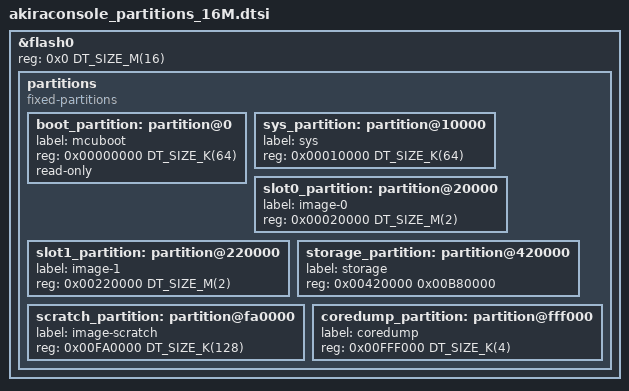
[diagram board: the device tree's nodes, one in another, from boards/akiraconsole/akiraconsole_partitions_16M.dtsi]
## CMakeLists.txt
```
# SPDX-License-Identifier: GPL-3.0-only
cmake_minimum_required(VERSION 3.20.0)

# Suppress Kconfig warnings-as-errors so undefined symbols (during incremental
# migration) do not abort the configuration phase.
set(KCONFIG_WARN_UNDEF OFF CACHE BOOL "" FORCE)
set(KCONFIG_WERROR     OFF CACHE BOOL "" FORCE)

# Board root — this repo contains the `boards/akiraconsole` board definition.
list(APPEND BOARD_ROOT ${CMAKE_CURRENT_LIST_DIR})
list(APPEND DTS_ROOT   ${CMAKE_CURRENT_LIST_DIR})

# AkiraOS is fetched by west into the `akiraos/` sub-directory next to this repo.
find_package(Zephyr REQUIRED HINTS $ENV{ZEPHYR_BASE})
project(akiraconsole_firmware VERSION 1.4.9)

# AkiraOS application sources are provided by the platform repo.
# MUST use add_subdirectory() — not include() — so that CMake sets
# CMAKE_CURRENT_SOURCE_DIR to the akiraos dir when processing its
# CMakeLists.txt.  target_sources() resolves relative paths from the
# internal CMAKE_CURRENT_SOURCE_DIR; include() does NOT update it.
if(EXISTS "${CMAKE_CURRENT_LIST_DIR}/../akiraos/CMakeLists.txt")
  add_subdirectory("${CMAKE_CURRENT_LIST_DIR}/../akiraos"
                   "${CMAKE_CURRENT_BINARY_DIR}/akiraos")
endif()

# ── WAMR include-path fix ───────────────────────────────────────────────────
# WAMR's runtime_lib.cmake registers its headers via directory-scoped
# include_directories().  When AkiraOS is pulled in via add_subdirectory()
# those directory-scoped includes are confined to the akiraos/ CMake scope
# and do NOT propagate to the parent (firmware) scope where 'app' target
# sources are actually compiled.  The result is fatal missing-header errors
# for platform_api_vmcore.h, bh_platform.h, and friends.
# Fix: explicitly add every WAMR include dir that runtime_lib.cmake would
# have registered globally in a standalone AkiraOS build.
if(CONFIG_AKIRA_WASM_RUNTIME)
  set(_wamr "${CMAKE_CURRENT_LIST_DIR}/../akiraos/modules/wasm-micro-runtime")
  target_include_directories(app PRIVATE
    ${_wamr}/core/shared/platform/include   # platform_api_vmcore.h, platform_common.h
    ${_wamr}/core/shared/platform/zephyr    # platform_internal.h (included by platform_common.h)
    ${_wamr}/core/shared/mem-alloc          # mem_alloc.h
    ${_wamr}/core/shared/utils              # bh_common.h, bh_log.h
    ${_wamr}/core/shared/utils/uncommon     # bh_assert.h variants
  )
  # platform_internal.h defines zephyr_fs_desc using struct fs_file_t / fs_dir_t
  # (Zephyr FS types from <zephyr/fs/fs_interface.h>).  When WAMR_BUILD_LIBC_WASI=0
  # zephyr_file.c — the only file that would pull in fs_interface.h — is excluded
  # from the build, leaving those types incomplete for every other translation unit.
  # Force-include the header so all app TUs see the complete struct definitions.
  target_compile_options(app PRIVATE
    "-include" "zephyr/fs/fs_interface.h"
  )
endif()

# ── AkiraConsole product-specific sources ──────────────────────────────────
# These files live in this repo and can be freely modified without touching
# AkiraOS.  Add new console-specific features here.
target_sources(app PRIVATE
  src/console_board.c
)

target_include_directories(app PRIVATE
  ${CMAKE_CURRENT_LIST_DIR}/src
)
```

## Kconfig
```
# SPDX-License-Identifier: Apache-2.0
#
# AkiraConsole Firmware — root Kconfig
#
# 1. Sources AkiraOS Kconfig tree (which itself sources Kconfig.zephyr),
#    making all AKIRA_* symbols available to the firmware config files.
# 2. Sources the product-level Kconfig so console-specific symbols
#    (AKIRA_CONSOLE_*) are visible in menuconfig and .conf files.
rsource "../akiraos/Kconfig"
rsource "src/Kconfig"
```

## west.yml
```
manifest:
  projects:
    # AkiraOS — the embedded platform (OS, drivers, WAMR runtime, native APIs).
    # Track the C0ns0l3-Firmware branch which is the validated working branch
    # for the AkiraConsole hardware.  Swap this for a release tag (e.g.
    # v1.4.10) once that tag is cut and CI is green.
    #
    # import: true  →  west reads AkiraOS/west.yml and pulls in Zephyr v4.3.0
    # plus all its HAL modules transitively.  This is the T2 manifest topology:
    # AkiraConsole-Firmware owns the entry-point; AkiraOS owns the Zephyr pin.
    - name: akiraos
      url: https://github.com/ArturR0k3r/AkiraOS
      revision: C0ns0l3-Firmware
      path: akiraos
      import: true   # brings in Zephyr + HALs from AkiraOS/west.yml

  self:
    path: akiraconsole-firmware
```

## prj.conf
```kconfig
# AkiraConsole product-level Kconfig overlay.
# Board-specific options (ESP32-S3, PSRAM, display, WiFi, BT …) are in
# boards/akiraconsole_esp32s3_procpu.conf and are merged automatically by west.
# Only add overrides here that are specific to the AkiraConsole *product* and
# should not live in the platform (AkiraOS) prj.conf.

# Enable AkiraOS WASM runtime — required gate for all AKIRA_WASM_* symbols.
CONFIG_AKIRA_WASM_RUNTIME=y

# App manager for persistent WASM install/uninstall.
CONFIG_AKIRA_APP_MANAGER=y
```

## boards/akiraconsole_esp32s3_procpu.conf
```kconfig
# BOARD_ZEPHYR: akiraconsole/esp32s3/procpu
# BOARD_CHIP: esp32s3
# BOARD_DESC: Akira Console (ESP32-S3 N16R8)
# BOARD_ALIAS: akiraconsole

# ESP32-S3 Specific Configuration
# ESP32-S3 N16R8 Module: 16MB Flash, 8MB PSRAM (OPI)

###############################################################################
# PSRAM (External SPIRAM) Configuration - 8MB OPI PSRAM
###############################################################################
CONFIG_ESP_SPIRAM=y
CONFIG_ESP_SPIRAM_SIZE=8388608
CONFIG_ESP_SPIRAM_HEAP_SIZE=4194304
CONFIG_SPIRAM_MODE_OCT=y
CONFIG_AKIRA_PSRAM=y
CONFIG_SPIRAM_TYPE_ESPPSRAM64=y
# WASM app thread stacks live in SRAM (not PSRAM) to avoid SPI0 bus conflict.
# On ESP32-S3, PSRAM and internal flash share SPI0; a direct flash read
# (e.g. fs_open via LittleFS) disables SPI0 PSRAM cache, crashing any thread
# whose stack is in PSRAM. 8 KB covers the deepest native call chain in AOT mode
# (WAMR AOT dispatch → native API → Zephyr display/SPI/DMA ≈ 3-4 KB worst case).
# The WAMR instance operand-stack (CONFIG_WAMR_STACK_SIZE=8192) is separate.
# 8 KB halves the SRAM heap requirement vs the old 16 KB, making allocation
# robust against WiFi/BT fragmentation of the 64 KB kernel heap.
CONFIG_AKIRA_WASM_APP_STACK_SIZE=8192
CONFIG_WAMR_AOT_SUPPORT=y
CONFIG_SPIRAM_SPEED_80M=y

# Enable MEMC driver - REQUIRED for PSRAM configuration
# This allows WAMR heap buffer to be placed in PSRAM instead of internal DRAM
CONFIG_MEMC=y

# Optional: Move read-only data to PSRAM to free internal DRAM 
CONFIG_SPIRAM_RODATA=y
CONFIG_SPIRAM_FETCH_INSTRUCTIONS=y



# Skip PSRAM memtest for faster boot (enable for debugging)
CONFIG_ESP_SPIRAM_MEMTEST=n

###############################################################################
# Thread Local Storage - REQUIRED for ESP32-S3 WAMR
###############################################################################
# ESP32-S3 has THREADPTR register (XCHAL_HAVE_THREADPTR=1).
# Without TLS enabled, Zephyr doesn't initialize or manage THREADPTR,
# leaving garbage values that cause crashes when WAMR accesses TLS.
CONFIG_THREAD_LOCAL_STORAGE=y

###############################################################################
# Memory Configuration (with PSRAM)
###############################################################################
# K-heap must exceed ADD_SIZE sum (BT=25600 + WiFi=19456 + POSIX=808 = 45864).
# If HEAP_MEM_POOL_SIZE < 45864, Zephyr uses 45864 as the effective K-heap —
# zero headroom for coex_init (esp_coex_common_malloc_internal_wrapper → k_malloc)
# → coex_env=NULL → ROM emi.c:164 assert.  65536 gives 19672 bytes of headroom.
# Large app allocations use akira_malloc_buffer() → PSRAM via shared_multi_heap.
CONFIG_HEAP_MEM_POOL_SIZE=65536
CONFIG_MAIN_STACK_SIZE=4096
CONFIG_SYSTEM_WORKQUEUE_STACK_SIZE=4096
# Shell backend thread stacks (uart + telnet): 4 K each is sufficient.
CONFIG_SHELL_STACK_SIZE=4096

# Shared Multi-Heap for PSRAM allocation
CONFIG_SHARED_MULTI_HEAP=y


###############################################################################
# Bluetooth
###############################################################################
CONFIG_BT=y
CONFIG_BT_PERIPHERAL=y
CONFIG_BT_DEVICE_NAME="AkiraOS"
CONFIG_BT_DEVICE_NAME_DYNAMIC=y
CONFIG_BT_DEVICE_NAME_MAX=32
CONFIG_BT_MAX_CONN=1
CONFIG_BT_L2CAP_TX_MTU=300
CONFIG_BT_BUF_ACL_RX_SIZE=300
CONFIG_BT_BUF_ACL_TX_SIZE=300


# GATT
CONFIG_BT_GATT_CLIENT=y
CONFIG_BT_ATT_PREPARE_COUNT=1
# Required for dynamic GATT service register/unregister (ble_app_service)
CONFIG_BT_GATT_DYNAMIC_DB=y

# BT Work Queue Stack Sizes
CONFIG_BT_RX_STACK_SIZE=2048
CONFIG_BT_HCI_TX_STACK_SIZE=1024

# Security
CONFIG_BT_SMP=y
CONFIG_BT_SIGNING=y
CONFIG_BT_BONDABLE=y
CONFIG_BT_KEYS_OVERWRITE_OLDEST=y
# Allow both legacy and Secure Connections pairing — older iOS/iPadOS uses legacy
CONFIG_BT_SMP_SC_PAIR_ONLY=n
# Service Changed indication — tells bonded peers (iOS/Android/Windows) to
# re-discover GATT database when firmware updates the attribute table.
# Without this, hosts cache stale handles and disconnect with 0x13.
CONFIG_BT_GATT_SERVICE_CHANGED=y
CONFIG_BT_GATT_CACHING=y

# Bond persistence — saves LTK / IRK to NVS so bonds survive reboot
# Without this the device loses keys on reset → security err 4 on reconnect
CONFIG_SETTINGS=y
CONFIG_SETTINGS_NVS=y
CONFIG_BT_SETTINGS=y

# Device Information Service (optional - disable to save memory)
# CONFIG_BT_DIS=y
# CONFIG_BT_DIS_STR_MAX=21
# Battery Service (optional - disable to save memory)
# Battery Service - mandatory for HOGP (iOS won't complete HID enumeration without it)
CONFIG_BT_BAS=y

###############################################################################
# HID & BT (BT-capable board — moved from prj.conf)
###############################################################################
CONFIG_AKIRA_HID=y
CONFIG_AKIRA_HID_MODE_KB_MOUSE=y
CONFIG_AKIRA_BT_HID=y


###############################################################################
# ESP32-S3 WiFi/BT
###############################################################################
# Base network stack — required for WIFI_ESP32 to satisfy NET_L2_ETHERNET deps
CONFIG_NETWORKING=y
CONFIG_NET_IPV4=y
CONFIG_WIFI=y
CONFIG_WIFI_ESP32=y
CONFIG_ESP_WIFI_HEAP_SPIRAM=y
# NOTE: CONFIG_ESP32_WIFI_NET_ALLOC_SPIRAM must NOT be set on ESP32-S3 when
# Bluetooth is active.  The BT controller ROM blob accesses WiFi coexistence
# state (emi.c) via shared DRAM structs; moving those to SPIRAM makes the ROM
# code fault with "BLE assert emi.c 164".  DRAM budget is met instead by the
# LVGL SPIRAM placement flags (LV_Z_VDB_CUSTOM_SECTION + MEMORY_POOL_CUSTOM)
# and reduced stack/buffer sizes — no WiFi/net noinit relocation needed.
CONFIG_ESP32_WIFI_STA_AUTO_DHCPV4=y
CONFIG_NET_L2_WIFI_MGMT=y
CONFIG_SHELL_BACKEND_TELNET=y
CONFIG_SHELL_TELNET_SUPPORT_COMMAND=y
CONFIG_NET_SOCKETS_OFFLOAD=y

# Bluetooth Controller Configuration
CONFIG_ESP32_BT_CONTROLLER_STACK_SIZE=4096
CONFIG_ESP32_BT_CONTROLLER_TASK_PRIO=2

# SPI for display
CONFIG_SPI=y

# Sensor support
CONFIG_I2C=y
CONFIG_SENSOR=y

# Disable AMPDU if you're still having issues (reduces memory usage)
CONFIG_ESP32_WIFI_AMPDU_TX_ENABLED=n
CONFIG_ESP32_WIFI_AMPDU_RX_ENABLED=n
# AMPDU disabled → 6 static RX buffers is enough; saves ~3.2 KB vs default 10
CONFIG_ESP32_WIFI_STATIC_RX_BUFFER_NUM=6

# Place large static assets into PSRAM where available
CONFIG_AKIRA_FONTS_IN_PSRAM=y
CONFIG_AKIRA_FRAMEBUFFER_IN_PSRAM=y

###############################################################################
# WAMR Memory Configuration - Using PSRAM for large buffers
###############################################################################
# With CONFIG_MEMC=y and ESP32-S3 PSRAM support,
# the WAMR heap buffer is placed in external SPIRAM
# This allows much larger WAMR heap without consuming internal DRAM
# Configure WAMR heap size for PSRAM placement
CONFIG_WAMR_HEAP_SIZE=1048576

# Limit max containers to save memory
CONFIG_MAX_CONTAINERS=2

###############################################################################
# Logging - Use immediate mode for debugging
###############################################################################
CONFIG_LOG_MODE_IMMEDIATE=y

CONFIG_AKIRA_BT_ECHO=n
CONFIG_AKIRA_EMBEDDED_WEB=y

###############################################################################
# Display & Input
###############################################################################
CONFIG_DISPLAY=y
CONFIG_MIPI_DBI=y


###############################################################################
# SD Card Support — SPI-SDHC via GPIO11/12/13/14
# MOSI=GPIO11, SCK=GPIO12, MISO=GPIO13, CS=GPIO14
# DTS node spi_sdhc0 on SPI2 (see akiraconsole_esp32s3_procpu.overlay)
# DISK_DRIVER_SDMMC is auto-selected by DTS (zephyr,sdmmc-disk node enabled)
###############################################################################
CONFIG_AKIRA_SD_CARD=y
CONFIG_SDHC=y
CONFIG_SDMMC_STACK=y
CONFIG_FILE_SYSTEM=y
CONFIG_FAT_FILESYSTEM_ELM=y
CONFIG_FS_FATFS_LFN=y
CONFIG_AKIRA_APP_SOURCE_SD=y


###############################################################################
# USB Stack
# HID only: 8–64 byte interrupt transfers. 2 KB is sufficient for the
# DWC2 IRQ bottom-half and the USBD event dispatcher.
###############################################################################
CONFIG_UDC_DWC2_STACK_SIZE=2048
CONFIG_USBD_THREAD_STACK_SIZE=2048

###############################################################################
# LR1121 LoRa Transceiver Support
###############################################################################
CONFIG_AKIRA_MODULE_RF=n
CONFIG_AKIRA_RF_FRAMEWORK=n
CONFIG_AKIRA_LR1121=n

###############################################################################
# TFT Display Driver — DC=GPIO9, RST=GPIO45, CS=GPIO10 (same for both)
# Default: ST7789V.  To use AkiraOS ILI9341, swap the three lines below:
#   comment ST7789V + MIPI_DBI_SPI, uncomment AKIRA_ILI9341_DRIVER.
###############################################################################
CONFIG_ST7789V=y
CONFIG_MIPI_DBI_SPI=y
#CONFIG_AKIRA_ILI9341_DRIVER=y

# Display and SPI log levels — DBG floods LOG_MODE_IMMEDIATE and stalls SPI
CONFIG_DISPLAY_LOG_LEVEL_WRN=y
CONFIG_MIPI_DBI_LOG_LEVEL_WRN=y
CONFIG_SPI_LOG_LEVEL_WRN=y


###############################################################################
# Flash configuration
###############################################################################
CONFIG_ESPTOOLPY_FLASHSIZE_16MB=y
CONFIG_ESPTOOLPY_FLASHMODE_DIO=y
CONFIG_ESPTOOLPY_FLASHFREQ_40M=y


###############################################################################
# Akira USB
###############################################################################
CONFIG_AKIRA_USB=y
CONFIG_AKIRA_USB_HID=y

CONFIG_USBD_LOG_LEVEL_INF=n
CONFIG_USBD_HID_LOG_LEVEL_INF=n
CONFIG_UDC_DRIVER_LOG_LEVEL_WRN=n
CONFIG_UDC_DRIVER_LOG_LEVEL_INF=n

###############################################################################
# Sensors - LSM6DS3 IMU on I2C0 (SDA=GPIO8, SCL=GPIO18)
# LSM6DS3TR-C shares WHO_AM_I 0x6A with LSM6DSL — no custom driver needed
###############################################################################
CONFIG_AKIRA_LSM6DS3_DRIVER=y
# WASM-level Timer/I2C APIs
CONFIG_AKIRA_WASM_TIMER=y

###############################################################################
# IPC / HID — PSRAM build: AKIRA_BULK_BSS routes arrays to .ext_ram.bss.
# MSG_MAX_SIZE=256 and QUEUE_DEPTH=4 are board overrides above prj.conf defaults.
###############################################################################
CONFIG_AKIRA_HID_MAX_ACTIONS=16
CONFIG_AKIRA_IPC_MSG_MAX_SIZE=256
CONFIG_AKIRA_IPC_QUEUE_DEPTH=4
CONFIG_AKIRA_WASM_I2C=y

###############################################################################
# WASM API Surface — hardware-specific APIs enabled on this board
###############################################################################
CONFIG_AKIRA_WASM_HID=y
CONFIG_AKIRA_WASM_POWER=y

###############################################################################
# Input subsystem — activates gpio-keys DTS driver for AkiraConsole buttons
###############################################################################
CONFIG_INPUT=y
CONFIG_AKIRA_INPUT_API=y
CONFIG_AKIRA_WASM_INPUT=y

###############################################################################
# System API — SD card WASM scanner (requires app.control cap, SD card above)
###############################################################################
CONFIG_AKIRA_SYSTEM_API=y

###############################################################################
# Boot shell — auto-launch akira_shell WASM app after app_manager_init()
# NOTE: With CONFIG_AKIRA_OS_SHELL=y the OS shell starts via SYS_INIT at
# APPLICATION level and does not need BOOT_SHELL.  Keep BOOT_SHELL entries
# only while WASM akira_shell is still installed during the transition.
###############################################################################
CONFIG_AKIRA_BOOT_SHELL=n
# CONFIG_AKIRA_BOOT_SHELL_NAME="akira_shell"
# CONFIG_AKIRA_BOOT_SHELL_RESTART=y

###############################################################################
# Native OS Shell (LVGL-based, C code, runs as a Zephyr thread)
# Replaces the WASM akira_shell app. Depends on DISPLAY && LVGL.
###############################################################################
CONFIG_AKIRA_OS_SHELL=y
CONFIG_AKIRA_HOME_BUTTON_GPIO=17
CONFIG_AKIRA_OS_VERSION="1.4.9-Gl1tch"

###############################################################################
# LVGL — required by the native OS shell
# VDB (virtual draw buffer) and LVGL heap are placed in SPIRAM via the
# .lvgl_buf / .lvgl_heap linker sections (ESP32-S3 GDMA covers PSRAM).
# This frees ~62 KB of internal DRAM for Zephyr thread stacks and BT/USB.
###############################################################################
CONFIG_LVGL=y
CONFIG_LV_COLOR_DEPTH_16=y
CONFIG_LV_Z_VDB_SIZE=10
CONFIG_LV_Z_VDB_CUSTOM_SECTION=y
CONFIG_LV_Z_MEM_POOL_SIZE=32768
CONFIG_LV_Z_MEMORY_POOL_CUSTOM_SECTION=y
CONFIG_LV_FONT_MONTSERRAT_14=y
CONFIG_LV_FONT_MONTSERRAT_20=y
CONFIG_LV_FONT_MONTSERRAT_48=y  # large app-grid icons and status bar symbols
CONFIG_LV_USE_LABEL=y
CONFIG_LV_USE_BUTTON=y
CONFIG_LV_USE_LIST=y
CONFIG_LV_USE_BAR=y
CONFIG_LV_USE_SLIDER=y
CONFIG_LV_USE_SWITCH=y
CONFIG_LV_USE_MSGBOX=y
CONFIG_LV_USE_KEYBOARD=y
CONFIG_LV_USE_ROLLER=y
CONFIG_LV_USE_SPINNER=y
CONFIG_LV_USE_IMAGE=y
CONFIG_LV_USE_ARC=y
CONFIG_LV_USE_THEME_DEFAULT=y
# Flush thread runs at priority 5 — above WASM apps (14) but below system work (0)
CONFIG_LV_Z_FLUSH_THREAD_PRIORITY=5
CONFIG_LV_Z_FLUSH_THREAD_STACK_SIZE=2048
CONFIG_AKIRA_WASM_SETTINGS=y
CONFIG_AKIRA_WASM_NET=y

# Network WASM API — board-level overrides (prj.conf sets the defaults).
# akiraconsole has PSRAM so we can afford larger streams and event queue.
CONFIG_AKIRA_NET_MAX_STREAMS=8
CONFIG_AKIRA_NET_POLL_STACK_SIZE=2048
CONFIG_AKIRA_NET_EVENT_QUEUE_DEPTH=16
# NET_SOCKETS_SERVICE is a dispatcher-only thread; 2 KB is sufficient (was 4 KB)
CONFIG_NET_SOCKETS_SERVICE_STACK_SIZE=2048
CONFIG_AKIRA_WASM_BLE=y
# Audit ring buffer: 16 entries × 68 bytes = saves ~1 KB vs default 32
CONFIG_AKIRA_AUDIT_LOG_SIZE=16
```

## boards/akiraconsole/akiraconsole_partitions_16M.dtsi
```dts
/*
 * AkiraConsole — 16 MB flash partition table (MCUboot, 2 MB image slots)
 *
 * Flash layout (16 MB = 0x1000000):
 *
 *   0x000000  boot_partition   (mcuboot)    64 KB
 *   0x010000  sys_partition    (sys)        64 KB
 *   0x020000  slot0_partition  (image-0)     2 MB
 *   0x220000  slot1_partition  (image-1)     2 MB
 *   0x420000  storage_partition             11.5 MB
 *   0xFA0000  scratch_partition (swap)      128 KB
 *   0xFFF000  coredump_partition              4 KB
 *
 * SPDX-License-Identifier: Apache-2.0
 */

/* Override flash size: hardware uses 16 MB, base dtsi declares 8 MB */
&flash0 {
	reg = <0x0 DT_SIZE_M(16)>;

	partitions {
		compatible = "fixed-partitions";
		#address-cells = <1>;
		#size-cells = <1>;

		boot_partition: partition@0 {
			label = "mcuboot";
			reg = <0x00000000 DT_SIZE_K(64)>;
			read-only;
		};

		sys_partition: partition@10000 {
			label = "sys";
			reg = <0x00010000 DT_SIZE_K(64)>;
		};

		slot0_partition: partition@20000 {
			label = "image-0";
			reg = <0x00020000 DT_SIZE_M(2)>;
		};

		slot1_partition: partition@220000 {
			label = "image-1";
			reg = <0x00220000 DT_SIZE_M(2)>;
		};

		storage_partition: partition@420000 {
			label = "storage";
			reg = <0x00420000 0x00B80000>; /* 11.5 MB */
		};

		scratch_partition: partition@fa0000 {
			label = "image-scratch";
			reg = <0x00FA0000 DT_SIZE_K(128)>;
		};

		coredump_partition: partition@fff000 {
			label = "coredump";
			reg = <0x00FFF000 DT_SIZE_K(4)>;
		};
	};
};
```

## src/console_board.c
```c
// SPDX-License-Identifier: GPL-3.0-only
/**
 * @file console_board.c
 * @brief AkiraConsole product-level board initialisation
 *
 * Runs via Zephyr's SYS_INIT mechanism at APPLICATION level — after the
 * AkiraOS platform HAL, filesystems, and runtime are already up.  This is
 * the right place for anything that is specific to the AkiraConsole *product*
 * rather than the AkiraOS platform:
 *
 *   - Boot-time button sampling (e.g. WiFi provisioning shortcut)
 *   - Product-specific log banner
 *   - Future: battery / charging status, LED patterns, etc.
 *
 * Add new console-specific initialisation here without modifying AkiraOS.
 */

#include <zephyr/kernel.h>
#include <zephyr/init.h>
#include <zephyr/logging/log.h>
#include <zephyr/drivers/gpio.h>
#include <zephyr/device.h>

LOG_MODULE_REGISTER(console_board, CONFIG_AKIRA_LOG_LEVEL);

/* ── Boot button (GPIO_0 pin 0, active-low with internal pull-up) ─────── */
#define BOOT_BUTTON_NODE DT_ALIAS(sw0)

#if DT_NODE_HAS_STATUS(BOOT_BUTTON_NODE, okay)
static const struct gpio_dt_spec boot_btn =
	GPIO_DT_SPEC_GET(BOOT_BUTTON_NODE, gpios);
#endif

/* Set to true by early boot sampling when the user holds the BOOT button. */
static bool s_wifi_prov_requested;

bool akira_console_wifi_prov_requested(void)
{
	return s_wifi_prov_requested;
}

/* ── Initialisation ────────────────────────────────────────────────────── */

static int console_board_init(void)
{
	LOG_INF("AkiraConsole board: " CONFIG_AKIRA_CONSOLE_PRODUCT_NAME);

#if defined(CONFIG_AKIRA_CONSOLE_BOOT_BUTTON_WIFI_PROV) && \
    DT_NODE_HAS_STATUS(BOOT_BUTTON_NODE, okay)
	if (!device_is_ready(boot_btn.port)) {
		LOG_WRN("Boot button GPIO not ready — provisioning shortcut disabled");
		return 0;
	}

	if (gpio_pin_configure_dt(&boot_btn, GPIO_INPUT) < 0) {
		LOG_WRN("Failed to configure boot button");
		return 0;
	}

	/* Button is active-low: reading 0 means pressed */
	if (gpio_pin_get_dt(&boot_btn) == 0) {
		s_wifi_prov_requested = true;
		LOG_WRN("BOOT button held at power-on — WiFi provisioning requested");
	}
#endif /* CONFIG_AKIRA_CONSOLE_BOOT_BUTTON_WIFI_PROV */

	return 0;
}

/*
 * APPLICATION priority runs after Zephyr drivers and kernel services are
 * ready, but the prio offset (99) keeps this after AkiraOS platform init
 * (which uses lower numbers).
 */
SYS_INIT(console_board_init, APPLICATION, 99);
```
